# RT584ZCM33 register map
Series: ARMv8-M Mainline; File version: 1.0
CPU: CM33 r0p0, little endian, MPU, no FPU, VTOR, 3 interrupt priority bits
Registers are 32-bit, read-write, reset 0x0 unless marked. A register's access mark holds for its fields unless they carry their own. Offsets are from the block's base; [hi:lo] are bit positions.

## TIMER0_Non-Secure — TIMER0 Non-Secure Register block
Base 0x4000A000
Same registers: TIMER1_Non-Secure 0x4000B000, TIMER2_Non-Secure 0x4000C000, TIMER0_Secure 0x5000A000, TIMER1_Secure 0x5000B000, TIMER2_Secure 0x5000C000
0x00 T0_LOAD_REG — The timer initial value. Timer update the down initial value after write this register. This register also the timer repeated value in periodic mode.
0x04 T0_VALUE_REG ro — The timer current value. This value is from timerClk domain synchronized to PCLK domain.
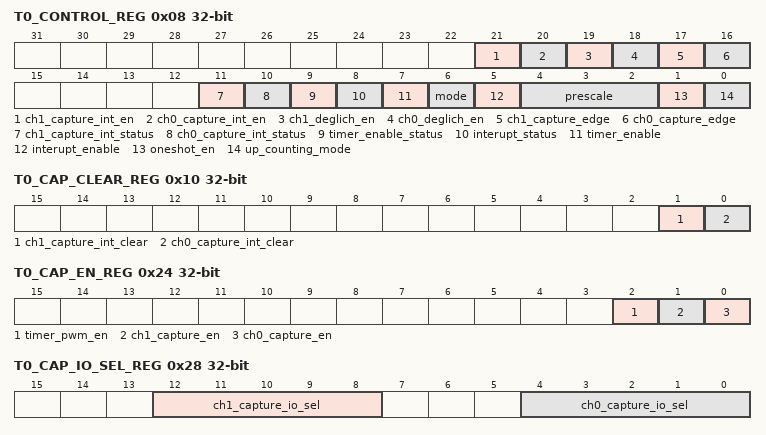
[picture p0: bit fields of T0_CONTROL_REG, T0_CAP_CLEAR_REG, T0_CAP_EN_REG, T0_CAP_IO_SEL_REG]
0x08 T0_CONTROL_REG — t0 control
  [21] ch1_capture_int_en — ch1 capture interrupt enable 0:disable 1:enable
    0=B_21 (ch1 capture interrupt enable 0:disable 1:enable)
  [20] ch0_capture_int_en — ch0 capture interrupt enable 0:disable 1:enable
    0=B_20 (ch0 capture interrupt enable 0:disable 1:enable)
  [19] ch1_deglich_en — ch1 input deglich enable 0: disable 1:enable
    0=B_19 (ch1 input deglich enable 0: disable 1:enable)
  [18] ch0_deglich_en — ch0 input deglich enable 0: disable 1:enable
    0=B_18 (ch0 input deglich enable 0: disable 1:enable)
  [17] ch1_capture_edge — ch1 cpature edge select 0: posedge 1:negedge
    0=B_17 (ch1 cpature edge select 0: posedge 1:negedge)
  [16] ch0_capture_edge — ch0 cpature edge select 0: posedge 1:negedge
    0=B_16 (ch0 cpature edge select 0: posedge 1:negedge)
  [11] ch1_capture_int_status ro — timer ch1 capture interupt status
    0=B_11 (timer ch1 capture interupt status)
  [10] ch0_capture_int_status ro — timer ch0 capture interupt status
    0=B_10 (timer ch0 capture interupt status)
  [9] timer_enable_status ro — timer enable status at timer clk domain
    0=B_9 (timer enable status at timer clk domain)
  [8] interupt_status ro — timer interupt status
    0=B_8 (timer interupt status)
  [7] timer_enable — timer enable; one shot mode trigger 0:disable 1:enable
    0=B_7_ITEM0 (disable); 1=B_7_ITEM1 (enable)
  [6] mode — timer mode select 0:free running mode 1:periodic mode
    0=B_6_ITEM0 (free running mode); 1=B_6_ITEM1 (periodic mode)
  [5] interupt_enable — timer interupt enable 0:disable 1:enable
    0=B_5_ITEM0 (disable); 1=B_5_ITEM1 (enable)
  [4:2] prescale — 0: timer clock is divided by 1 1: timer clock is divided by 16 2: timer clock is divided by 256 3: timer clock is divided by 2 4: timer clock is divided by 8 5: timer clock is divided by 32 6: timer clock is divided by 128 7: timer clock is divided by 1024 only valid when prescale_val=0
    0=B_2_to_4_ITEM0 (timer clock is divided by 1); 1=B_2_to_4_ITEM1 (timer clock is divided by 16); 2=B_2_to_4_ITEM2 (timer clock is divided by 256); 3=B_2_to_4_ITEM3 (timer clock is divided by 2); 4=B_2_to_4_ITEM4 (timer clock is divided by 8); 5=B_2_to_4_ITEM5 (timer clock is divided by 32); 6=B_2_to_4_ITEM6 (timer clock is divided by 128); 7=B_2_to_4_ITEM7 (timer clock is divided by 1024)
  [1] oneshot_en — timer one shot mode enable 0: one shot mode disable 1: one shot mode enable
    0=B_1_ITEM0 (one shot mode disable); 1=B_1_ITEM1 (one shot mode enable)
  [0] up_counting_mode — timer up counting mode enable 0: down counting mode 1: up counting mode
    0=B_0_ITEM0 (down counting mode); 1=B_0_ITEM1 (up counting mode)
0x0C T0_CLEAR_REG wo — Write any value to clear timer interupt status
0x10 T0_CAP_CLEAR_REG wo — t0 cap clear
  [1] ch1_capture_int_clear — Write any value to clear timer ch1_capture interupt status
    0=B_1 (Write any value to clear timer ch1_capture interupt status)
  [0] ch0_capture_int_clear — Write any value to clear timer ch0_capture interupt status
    0=B_0 (Write any value to clear timer ch0_capture interupt status)
0x14 T0_CH0_CAP_VAL_REG ro — ch0 capture value, clear when timer load
0x18 T0_CH1_CAP_VAL_REG ro — ch1 capture value, clear when timer load
0x1C T0_PRESCALE_REG — t0 prescale
  [9:0] prescale_val — timer clock is divided by prescale+1, only valid when>0
0x20 T0_EX_VAL_REG — timer expired value
0x24 T0_CAP_EN_REG — t0 cap en
  [2] timer_pwm_en — timer pwm enable 0: disable 1: enable
    0=B_2_ITEM0 (disable); 1=B_2_ITEM1 (enable)
  [1] ch1_capture_en — capture ch1 interupt enable 0: disable 1: enable
    0=B_1_ITEM0 (disable); 1=B_1_ITEM1 (enable)
  [0] ch0_capture_en — capture ch0 interupt enable 0: disable 1: enable
    0=B_0_ITEM0 (disable); 1=B_0_ITEM1 (enable)
0x28 T0_CAP_IO_SEL_REG — t0 cap io sel
  [12:8] ch1_capture_io_sel — select target GPIO as ch1
    0=B_8_to_12 (select target GPIO as ch1)
  [4:0] ch0_capture_io_sel — select target GPIO as ch0
    0=B_0_to_4 (select target GPIO as ch0)
0x2C T0_THD_REG — timer threshold for generate simple PWM waveform
0x30 T0_PHA_REG — t0 pha
  [0] pha — timer pha for generate simple PWM waveform
    0=B_0 (timer pha for generate simple PWM waveform)
